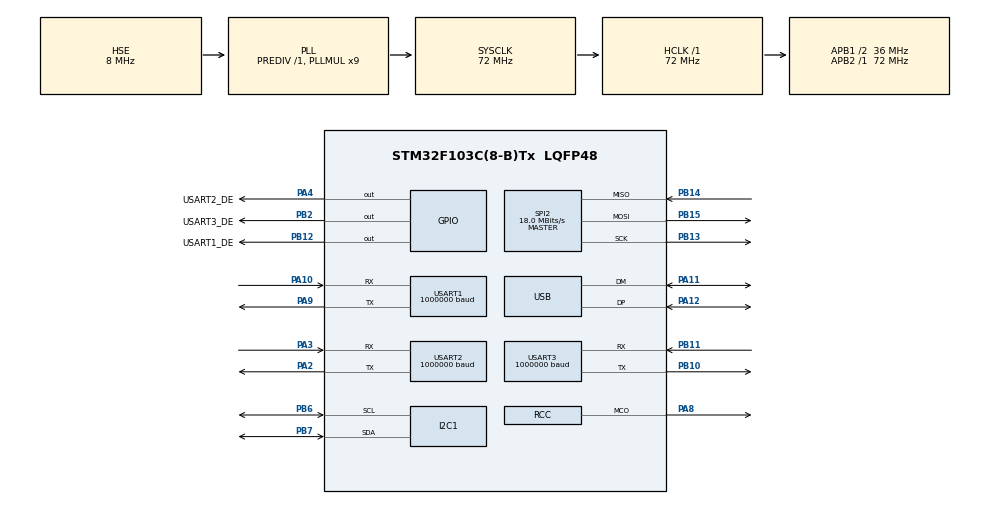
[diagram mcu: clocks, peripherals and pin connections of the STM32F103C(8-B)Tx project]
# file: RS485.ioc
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Dma.Request0=USART1_RX
Dma.Request1=USART1_TX
Dma.Request2=USART2_RX
Dma.Request3=USART2_TX
Dma.Request4=USART3_RX
Dma.Request5=USART3_TX
Dma.USART1_RX.0.Direction=DMA_PERIPH_TO_MEMORY
Dma.USART1_RX.0.Instance=DMA1_Channel5
Dma.USART1_RX.0.MemDataAlignment=DMA_MDATAALIGN_BYTE
Dma.USART1_RX.0.MemInc=DMA_MINC_ENABLE
Dma.USART1_RX.0.Mode=DMA_NORMAL
Dma.USART1_RX.0.PeriphDataAlignment=DMA_PDATAALIGN_BYTE
Dma.USART1_RX.0.PeriphInc=DMA_PINC_DISABLE
Dma.USART1_RX.0.Priority=DMA_PRIORITY_LOW
Dma.USART1_TX.1.Direction=DMA_MEMORY_TO_PERIPH
Dma.USART1_TX.1.Instance=DMA1_Channel4
Dma.USART1_TX.1.MemDataAlignment=DMA_MDATAALIGN_BYTE
Dma.USART1_TX.1.MemInc=DMA_MINC_ENABLE
Dma.USART1_TX.1.Mode=DMA_CIRCULAR
Dma.USART1_TX.1.PeriphDataAlignment=DMA_PDATAALIGN_BYTE
Dma.USART1_TX.1.PeriphInc=DMA_PINC_DISABLE
Dma.USART1_TX.1.Priority=DMA_PRIORITY_LOW
Dma.USART2_RX.2.Direction=DMA_PERIPH_TO_MEMORY
Dma.USART2_RX.2.Instance=DMA1_Channel6
Dma.USART2_RX.2.MemDataAlignment=DMA_MDATAALIGN_BYTE
Dma.USART2_RX.2.MemInc=DMA_MINC_ENABLE
Dma.USART2_RX.2.Mode=DMA_NORMAL
Dma.USART2_RX.2.PeriphDataAlignment=DMA_PDATAALIGN_BYTE
Dma.USART2_RX.2.PeriphInc=DMA_PINC_DISABLE
Dma.USART2_RX.2.Priority=DMA_PRIORITY_LOW
Dma.USART2_TX.3.Direction=DMA_MEMORY_TO_PERIPH
Dma.USART2_TX.3.Instance=DMA1_Channel7
Dma.USART2_TX.3.MemDataAlignment=DMA_MDATAALIGN_BYTE
Dma.USART2_TX.3.MemInc=DMA_MINC_ENABLE
Dma.USART2_TX.3.Mode=DMA_CIRCULAR
Dma.USART2_TX.3.PeriphDataAlignment=DMA_PDATAALIGN_BYTE
Dma.USART2_TX.3.PeriphInc=DMA_PINC_DISABLE
Dma.USART2_TX.3.Priority=DMA_PRIORITY_LOW
Dma.USART3_RX.4.Direction=DMA_PERIPH_TO_MEMORY
Dma.USART3_RX.4.Instance=DMA1_Channel3
Dma.USART3_RX.4.MemDataAlignment=DMA_MDATAALIGN_BYTE
Dma.USART3_RX.4.MemInc=DMA_MINC_ENABLE
Dma.USART3_RX.4.Mode=DMA_NORMAL
Dma.USART3_RX.4.PeriphDataAlignment=DMA_PDATAALIGN_BYTE
Dma.USART3_RX.4.PeriphInc=DMA_PINC_DISABLE
Dma.USART3_RX.4.Priority=DMA_PRIORITY_LOW
Dma.USART3_TX.5.Direction=DMA_MEMORY_TO_PERIPH
Dma.USART3_TX.5.Instance=DMA1_Channel2
Dma.USART3_TX.5.MemDataAlignment=DMA_MDATAALIGN_BYTE
Dma.USART3_TX.5.MemInc=DMA_MINC_ENABLE
Dma.USART3_TX.5.Mode=DMA_CIRCULAR
Dma.USART3_TX.5.PeriphDataAlignment=DMA_PDATAALIGN_BYTE
Dma.USART3_TX.5.PeriphInc=DMA_PINC_DISABLE
Dma.USART3_TX.5.Priority=DMA_PRIORITY_LOW
Mcu.Family=STM32F1
Mcu.Name=STM32F103C(8-B)Tx
Mcu.Package=LQFP48
NVIC.DMA1_Channel2_IRQn=true\:0\:0\:false\:false\:true\:false\:true\:true
NVIC.DMA1_Channel3_IRQn=true\:0\:0\:false\:false\:true\:false\:true\:true
NVIC.DMA1_Channel4_IRQn=true\:0\:0\:false\:false\:true\:false\:true\:true
NVIC.DMA1_Channel5_IRQn=true\:0\:0\:false\:false\:true\:false\:true\:true
NVIC.DMA1_Channel6_IRQn=true\:0\:0\:false\:false\:true\:false\:true\:true
NVIC.DMA1_Channel7_IRQn=true\:0\:0\:false\:false\:true\:false\:true\:true
NVIC.PriorityGroup=NVIC_PRIORITYGROUP_4
NVIC.USART1_IRQn=true\:0\:0\:false\:false\:true\:true\:true\:true
NVIC.USART2_IRQn=true\:0\:0\:false\:false\:true\:true\:true\:true
NVIC.USART3_IRQn=true\:0\:0\:false\:false\:true\:true\:true\:true
NVIC.USB_LP_CAN1_RX0_IRQn=true\:0\:0\:false\:false\:true\:false\:true\:true
PA10.Mode=Asynchronous
PA10.Signal=USART1_RX
PA11.Mode=Device
PA11.Signal=USB_DM
PA12.Mode=Device
PA12.Signal=USB_DP
PA13.Mode=Serial_Wire
PA13.Signal=SYS_JTMS-SWDIO
PA14.Mode=Serial_Wire
PA14.Signal=SYS_JTCK-SWCLK
PA2.Mode=Asynchronous
PA2.Signal=USART2_TX
PA3.Mode=Asynchronous
PA3.Signal=USART2_RX
PA4.GPIO_Label=USART2_DE
PA4.Signal=GPIO_Output
PA8.Mode=Clock-out
PA8.Signal=RCC_MCO
PA9.Mode=Asynchronous
PA9.Signal=USART1_TX
PB10.Mode=Asynchronous
PB10.Signal=USART3_TX
PB11.Mode=Asynchronous
PB11.Signal=USART3_RX
PB12.GPIO_Label=USART1_DE
PB12.Signal=GPIO_Output
PB13.Mode=Full_Duplex_Master
PB13.Signal=SPI2_SCK
PB14.Mode=Full_Duplex_Master
PB14.Signal=SPI2_MISO
PB15.Mode=Full_Duplex_Master
PB15.Signal=SPI2_MOSI
PB2.GPIO_Label=USART3_DE
PB2.Signal=GPIO_Output
PB6.Mode=I2C
PB6.Signal=I2C1_SCL
PB7.Mode=I2C
PB7.Signal=I2C1_SDA
PD0-OSC_IN.Mode=HSE-External-Oscillator
PD0-OSC_IN.Signal=RCC_OSC_IN
PD1-OSC_OUT.Mode=HSE-External-Oscillator
PD1-OSC_OUT.Signal=RCC_OSC_OUT
ProjectManager.HeapSize=0x200
ProjectManager.StackSize=0x400
ProjectManager.TargetToolchain=MDK-ARM V5.32
RCC.AHBFreq_Value=72000000
RCC.APB1CLKDivider=RCC_HCLK_DIV2
RCC.APB1Freq_Value=36000000
RCC.APB1TimFreq_Value=72000000
RCC.APB2Freq_Value=72000000
RCC.APB2TimFreq_Value=72000000
RCC.HCLKFreq_Value=72000000
RCC.PLLMUL=RCC_PLL_MUL9
RCC.PLLSourceVirtual=RCC_PLLSOURCE_HSE
RCC.RCC_MCOSource=RCC_MCO1SOURCE_PLLCLK
RCC.SYSCLKFreq_VALUE=72000000
RCC.SYSCLKSource=RCC_SYSCLKSOURCE_PLLCLK
RCC.USBFreq_Value=48000000
RCC.USBPrescaler=RCC_USBCLKSOURCE_PLL_DIV1_5
SPI2.CalculateBaudRate=18.0 MBits/s
SPI2.Direction=SPI_DIRECTION_2LINES
SPI2.Mode=SPI_MODE_MASTER
SPI2.VirtualType=VM_MASTER
USART1.BaudRate=1000000
USART1.Parity=PARITY_EVEN
USART1.VirtualMode=VM_ASYNC
USART1.WordLength=WORDLENGTH_9B
USART2.BaudRate=1000000
USART2.Parity=PARITY_EVEN
USART2.VirtualMode=VM_ASYNC
USART2.WordLength=WORDLENGTH_8B
USART3.BaudRate=1000000
USART3.Parity=PARITY_EVEN
USART3.VirtualMode=VM_ASYNC
USB_DEVICE.CLASS_NAME_FS=CDC
USB_DEVICE.VirtualMode=Cdc
USB_DEVICE.VirtualModeFS=Cdc_FS
VP_USB_DEVICE_VS_USB_DEVICE_CDC_FS.Mode=CDC_FS
board=custom

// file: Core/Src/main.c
/* USER CODE BEGIN Header */
/**
  ******************************************************************************
  * @file           : main.c
  * @brief          : Main program body
  ******************************************************************************
  * @attention
  *
  * Copyright (c) 2026 STMicroelectronics.
  * All rights reserved.
  *
  * This software is licensed under terms that can be found in the LICENSE file
  * in the root directory of this software component.
  * If no LICENSE file comes with this software, it is provided AS-IS.
  *
  ******************************************************************************
  */
/* USER CODE END Header */
#include "main.h"
#include "dma.h"
#include "i2c.h"
#include "spi.h"
#include "usart.h"
#include "usb_device.h"
#include "gpio.h"
#include "usbd_cdc_if.h"
#include "ssd1306.h"
#include "oled_ui.h"
#include <string.h>

void SystemClock_Config(void);

int main(void)
{
  uint32_t oled_update_tick = 0U;

  /* MCU Configuration--------------------------------------------------------*/

  /* Reset of all peripherals, Initializes the Flash interface and the Systick. */
  HAL_Init();

  /* Configure the system clock */
  SystemClock_Config();

  /* Initialize all configured peripherals */
  MX_GPIO_Init();
  MX_DMA_Init();
  MX_I2C1_Init();
  MX_USART1_UART_Init();
  MX_USART2_UART_Init();
  MX_USART3_UART_Init();
  MX_USB_DEVICE_Init();
  MX_USART_DMA_Receive_Start();
  MX_SPI2_Init();
  /* USER CODE BEGIN 2 */
  SSD1306_Init();
  OLED_UI_Update();
  /* USER CODE END 2 */

  /* Infinite loop */
  while (1)
  {

    /* USER CODE BEGIN 3 */
    UART_USB_Process();
    if ((HAL_GetTick() - oled_update_tick) >= 500U)
    {
      oled_update_tick = HAL_GetTick();
      OLED_UI_Update();
    }
  }
  /* USER CODE END 3 */
}

void SystemClock_Config(void)
{
  RCC_OscInitTypeDef RCC_OscInitStruct = {0};
  RCC_ClkInitTypeDef RCC_ClkInitStruct = {0};
  RCC_PeriphCLKInitTypeDef PeriphClkInit = {0};

  /** Initializes the RCC Oscillators according to the specified parameters
  * in the RCC_OscInitTypeDef structure.
  */
  RCC_OscInitStruct.OscillatorType = RCC_OSCILLATORTYPE_HSE;
  RCC_OscInitStruct.HSEState = RCC_HSE_ON;
  RCC_OscInitStruct.HSEPredivValue = RCC_HSE_PREDIV_DIV1;
  RCC_OscInitStruct.HSIState = RCC_HSI_ON;
  RCC_OscInitStruct.PLL.PLLState = RCC_PLL_ON;
  RCC_OscInitStruct.PLL.PLLSource = RCC_PLLSOURCE_HSE;
  RCC_OscInitStruct.PLL.PLLMUL = RCC_PLL_MUL9;
  if (HAL_RCC_OscConfig(&RCC_OscInitStruct) != HAL_OK)
  {
    Error_Handler();
  }

  /** Initializes the CPU, AHB and APB buses clocks
  */
  RCC_ClkInitStruct.ClockType = RCC_CLOCKTYPE_HCLK|RCC_CLOCKTYPE_SYSCLK
                              |RCC_CLOCKTYPE_PCLK1|RCC_CLOCKTYPE_PCLK2;
  RCC_ClkInitStruct.SYSCLKSource = RCC_SYSCLKSOURCE_PLLCLK;
  RCC_ClkInitStruct.AHBCLKDivider = RCC_SYSCLK_DIV1;
  RCC_ClkInitStruct.APB1CLKDivider = RCC_HCLK_DIV2;
  RCC_ClkInitStruct.APB2CLKDivider = RCC_HCLK_DIV1;

  if (HAL_RCC_ClockConfig(&RCC_ClkInitStruct, FLASH_LATENCY_2) != HAL_OK)
  {
    Error_Handler();
  }
  PeriphClkInit.PeriphClockSelection = RCC_PERIPHCLK_USB;
  PeriphClkInit.UsbClockSelection = RCC_USBCLKSOURCE_PLL_DIV1_5;
  if (HAL_RCCEx_PeriphCLKConfig(&PeriphClkInit) != HAL_OK)
  {
    Error_Handler();
  }
  HAL_RCC_MCOConfig(RCC_MCO, RCC_MCO1SOURCE_PLLCLK, RCC_MCODIV_1);
}

void Error_Handler(void)
{
  __disable_irq();
  while (1)
  {
  }
}
